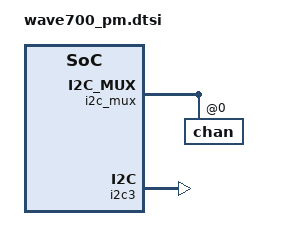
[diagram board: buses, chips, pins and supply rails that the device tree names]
// SPDX-License-Identifier: GPL-2.0
/*
 * Copyright (C) 2023 MaxLinear, Inc.
 */

#include "wave700.dtsi"

&i2c_mux {
	status = "okay";

	chan@0 {
		#address-cells = <1>;
		#size-cells = <0>;
		reg = <0>;

		hwmon@6d {
			compatible = "ltc2945";
			reg = <0x6d>;
			ltc2945,resistor = <3>; /* the unit is mohm */
			rail-name = "PWR_0V8_WV7";
		};
		hwmon@6e {
			compatible = "ltc2945";
			reg = <0x6e>;
			ltc2945,resistor = <10>; /* the unit is mohm */
			rail-name = "PWR_1V2_WV7";
		};
		hwmon@6f {
			compatible = "ltc2945";
			reg = <0x6f>;
			ltc2945,resistor = <25>; /* the unit is mohm */
			rail-name = "PWR_1V8_WV7";
		};
	};
};

&i2c3 {
	status = "okay";
};
